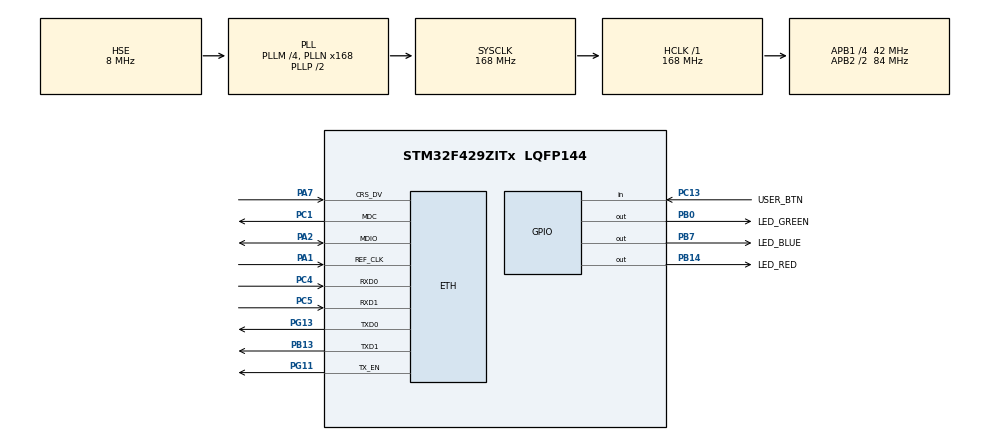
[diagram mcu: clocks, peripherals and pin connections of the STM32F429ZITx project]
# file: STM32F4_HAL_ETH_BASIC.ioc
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ETH.MediaInterface=ETH_MEDIA_INTERFACE_RMII
ETH.PhyAddress=0
LWIP.GATEWAY_ADDRESS=192.168.001.001
LWIP.IP_ADDRESS=192.168.001.100
LWIP.LWIP_DHCP=1
LWIP.LWIP_DNS=1
LWIP.LWIP_NETIF_LINK_CALLBACK=1
LWIP.NETMASK_ADDRESS=255.255.255.000
LWIP.Version=v2.1.2_Cube
Mcu.Family=STM32F4
Mcu.Name=STM32F429ZITx
Mcu.Package=LQFP144
NVIC.PriorityGroup=NVIC_PRIORITYGROUP_4
PA1.Mode=RMII
PA1.Signal=ETH_REF_CLK
PA13.Mode=Trace_Asynchronous_SW
PA13.Signal=SYS_JTMS-SWDIO
PA14.Mode=Trace_Asynchronous_SW
PA14.Signal=SYS_JTCK-SWCLK
PA2.Mode=RMII
PA2.Signal=ETH_MDIO
PA7.Mode=RMII
PA7.Signal=ETH_CRS_DV
PB0.GPIO_Label=LED_GREEN
PB0.Signal=GPIO_Output
PB13.Mode=RMII
PB13.Signal=ETH_TXD1
PB14.GPIO_Label=LED_RED
PB14.Signal=GPIO_Output
PB3.Mode=Trace_Asynchronous_SW
PB3.Signal=SYS_JTDO-SWO
PB7.GPIO_Label=LED_BLUE
PB7.Signal=GPIO_Output
PC1.Mode=RMII
PC1.Signal=ETH_MDC
PC13.GPIO_Label=USER_BTN
PC13.Signal=GPIO_Input
PC14/OSC32_IN.Mode=LSE-External-Oscillator
PC14/OSC32_IN.Signal=RCC_OSC32_IN
PC15/OSC32_OUT.Mode=LSE-External-Oscillator
PC15/OSC32_OUT.Signal=RCC_OSC32_OUT
PC4.Mode=RMII
PC4.Signal=ETH_RXD0
PC5.Mode=RMII
PC5.Signal=ETH_RXD1
PG11.Mode=RMII
PG11.Signal=ETH_TX_EN
PG13.Mode=RMII
PG13.Signal=ETH_TXD0
PH0/OSC_IN.Mode=HSE-External-Clock-Source
PH0/OSC_IN.Signal=RCC_OSC_IN
PH1/OSC_OUT.Mode=HSE-External-Clock-Source
PH1/OSC_OUT.Signal=RCC_OSC_OUT
ProjectManager.HeapSize=0x200
ProjectManager.StackSize=0x800
ProjectManager.TargetToolchain=STM32CubeIDE
RCC.48MHZClocksFreq_Value=48000000
RCC.AHBFreq_Value=168000000
RCC.APB1CLKDivider=RCC_HCLK_DIV4
RCC.APB1Freq_Value=42000000
RCC.APB1TimFreq_Value=84000000
RCC.APB2CLKDivider=RCC_HCLK_DIV2
RCC.APB2Freq_Value=84000000
RCC.APB2TimCLKDivider=2
RCC.APB2TimFreq_Value=168000000
RCC.CortexFreq_Value=168000000
RCC.HCLKFreq_Value=168000000
RCC.HSE_VALUE=8000000
RCC.HSI_VALUE=16000000
RCC.PLLM=4
RCC.PLLMUL=RCC_PLL_MUL9
RCC.PLLN=168
RCC.PLLQ=7
RCC.PLLSourceVirtual=RCC_PLLSOURCE_HSE
RCC.PRESCALERUSB=RCC_USBCLKSOURCE_PLL_DIV1_5
RCC.SYSCLKFreq_VALUE=168000000
RCC.SYSCLKSource=RCC_SYSCLKSOURCE_PLLCLK
RCC.SYSCLKSourceVirtual=RCC_SYSCLKSOURCE_PLLCLK
RCC.USBFreq_Value=48000000
RCC.VCOOutputFreq_Value=336000000
VP_LWIP_VS_Enabled.Mode=Enabled
board=NUCLEO-F429ZI

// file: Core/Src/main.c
/* USER CODE BEGIN Header */
/**
 ******************************************************************************
 * @file           : main.c
 * @brief          : Main program body
 ******************************************************************************
 * @attention
 *
 * <h2><center>&copy; Copyright (c) 2020 STMicroelectronics.
 * All rights reserved.</center></h2>
 *
 * This software component is licensed by ST under Ultimate Liberty license
 * SLA0044, the "License"; You may not use this file except in compliance with
 * the License. You may obtain a copy of the License at:
 *                             www.st.com/SLA0044
 *
 ******************************************************************************
 */
/* USER CODE END Header */

#include "main.h"
#include "lwip.h"
#include "gpio.h"

/* USER CODE BEGIN PV */
extern struct netif gnetif;

/* USER CODE END PV */

void SystemClock_Config(void);

/* USER CODE BEGIN 0 */
void ethernetif_notify_conn_changed(struct netif *netif)
{
	/* NOTE : This is function could be implemented in user file
	 when the callback is needed,
	 */
	if (netif_is_link_up(netif))
	{
		HAL_GPIO_WritePin(LED_GREEN_GPIO_Port, LED_GREEN_Pin, GPIO_PIN_SET);
		HAL_GPIO_WritePin(LED_RED_GPIO_Port, LED_RED_Pin, GPIO_PIN_RESET);
		printf("IP address: %s\n", ip4addr_ntoa(netif_ip4_addr(&gnetif)));
	}
	else
	{
		HAL_GPIO_WritePin(LED_GREEN_GPIO_Port, LED_GREEN_Pin, GPIO_PIN_RESET);
		HAL_GPIO_WritePin(LED_RED_GPIO_Port, LED_RED_Pin, GPIO_PIN_SET);
	}
}

/* USER CODE END 0 */

int main(void)
{

	/* MCU Configuration--------------------------------------------------------*/

	/* Reset of all peripherals, Initializes the Flash interface and the Systick. */
	HAL_Init();

	/* Configure the system clock */
	SystemClock_Config();

	/* Initialize all configured peripherals */
	MX_GPIO_Init();
	MX_LWIP_Init();
	/* USER CODE BEGIN 2 */
	ethernetif_notify_conn_changed(&gnetif);

	/* USER CODE END 2 */

	/* Infinite loop */
	while (1)
	{

		/* USER CODE BEGIN 3 */
		MX_LWIP_Process();
	}
	/* USER CODE END 3 */
}

void SystemClock_Config(void)
{
	RCC_OscInitTypeDef RCC_OscInitStruct =
	{ 0 };
	RCC_ClkInitTypeDef RCC_ClkInitStruct =
	{ 0 };

	/** Configure the main internal regulator output voltage
	 */
	__HAL_RCC_PWR_CLK_ENABLE();
	__HAL_PWR_VOLTAGESCALING_CONFIG(PWR_REGULATOR_VOLTAGE_SCALE1);
	/** Initializes the CPU, AHB and APB busses clocks
	 */
	RCC_OscInitStruct.OscillatorType = RCC_OSCILLATORTYPE_HSE;
	RCC_OscInitStruct.HSEState = RCC_HSE_BYPASS;
	RCC_OscInitStruct.PLL.PLLState = RCC_PLL_ON;
	RCC_OscInitStruct.PLL.PLLSource = RCC_PLLSOURCE_HSE;
	RCC_OscInitStruct.PLL.PLLM = 4;
	RCC_OscInitStruct.PLL.PLLN = 168;
	RCC_OscInitStruct.PLL.PLLP = RCC_PLLP_DIV2;
	RCC_OscInitStruct.PLL.PLLQ = 7;
	if (HAL_RCC_OscConfig(&RCC_OscInitStruct) != HAL_OK)
	{
		Error_Handler();
	}
	/** Initializes the CPU, AHB and APB busses clocks
	 */
	RCC_ClkInitStruct.ClockType = RCC_CLOCKTYPE_HCLK | RCC_CLOCKTYPE_SYSCLK
			| RCC_CLOCKTYPE_PCLK1 | RCC_CLOCKTYPE_PCLK2;
	RCC_ClkInitStruct.SYSCLKSource = RCC_SYSCLKSOURCE_PLLCLK;
	RCC_ClkInitStruct.AHBCLKDivider = RCC_SYSCLK_DIV1;
	RCC_ClkInitStruct.APB1CLKDivider = RCC_HCLK_DIV4;
	RCC_ClkInitStruct.APB2CLKDivider = RCC_HCLK_DIV2;

	if (HAL_RCC_ClockConfig(&RCC_ClkInitStruct, FLASH_LATENCY_5) != HAL_OK)
	{
		Error_Handler();
	}
}

void Error_Handler(void)
{
}

/************************ (C) COPYRIGHT STMicroelectronics *****END OF FILE****/
